# SCR_TC3xx register map
Vendor: Infineon; File version: 1.0
Registers are 8-bit, read-write, reset 0x0 unless marked. A register's access mark holds for its fields unless they carry their own. Offsets are from the block's base; [hi:lo] are bit positions; {n}, {i} and the like mark numbered series.

## SCR_SSC — SCR Synchronous serial channel
Base 0x00040000
0x09 SSC_CONOL ro — Control Register Low [Operation Mode] (SFR 0x89, RMAP 0)
  [3:0] BC — Bit Count Field. This field is loaded with the programmed data width value (BM) when the SSC is enabled. It then counts down with every shift bit. Note:This bit field is not to be written to. [rh]
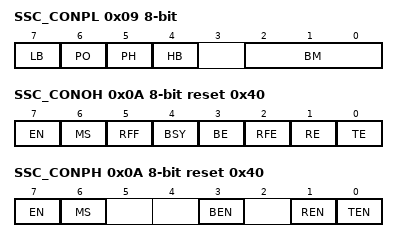
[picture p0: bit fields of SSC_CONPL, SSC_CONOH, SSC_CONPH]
0x09 SSC_CONPL (alternate view of SSC_CONOL) — Control Register Low [Programming Mode] (SFR 0x89, RMAP 0)
  [7] LB — Loop Back Control. This bit shall be set by software only in Master mode. [rw]
    0=NORMAL_OUTPUT; 1=RECEIVE_INPUT_IS_CONNECTED_WITH (Receive input is connected with transmit output (half-duplex mode))
  [6] PO — Clock Polarity Control. [rw]
    0=IDLE_LOW (Idle clock line is low, leading clock edge is low-to-high transition.); 1=IDLE_HIGH (Idle clock line is high, leading clock edge is high-to-low transition.)
  [5] PH — Clock Phase Control. [rw]
    0=LATCH_ON_TRAILING_EDGE (Shift transmit data on the leading clock edge, latch on trailing edge.); 1=LATCH_ON_LEADING_EDGE (Latch receive data on leading clock edge, shift on trailing edge.)
  [4] HB — Heading Control. [rw]
    0=LSB_FIRST (Transmit/Receive LSB First); 1=MSB_FIRST (Transmit/Receive MSB First)
  [2:0] BM — Data Width Selection. Note:The transfer and receive data width is maximum 8 bits. Transfer Data Width is 4...8 bits (<BM>+1). … [rw]
    0=RESERVED_DO_NOT_USE_THIS (Reserved. Do not use this combination.); 2=RESERVED_DO_NOT_USE_THIS_2 (Reserved. Do not use this combination.); {v}=TRANSFER_DATA_WIDTH_IS_{v+1}_BITS (v=3..7)
0x0A SSC_CONOH reset 0x40 — Control Register High [Operation Mode] (SFR 0x8A, RMAP 0)
  [7] EN — Enable Bit = 1 (needed for operating mode). Transmission and reception enabled. Access to status flags and M/S control. [rw]
  [6] MS — Master Select. This bit shall not be modified during operation mode. [rw]
    0=SLAVE_MODE_OPERATE_ON_SHIFT_CLOCK (Slave Mode. Operate on shift clock received via SCLK.); 1=MASTER_MODE_GENERATE_SHIFT_CLOCK (Master Mode. Generate shift clock and output it via SCLK.)
  [5] RFF ro — Receive FIFO Buffer Full Flag. Note:FIFO full will be deleted as soon as the receive buffer is read by software. [rh]
    0=RECEIVE_FIFO_IS_NOT_FULL; 1=RECEIVE_FIFO_IS_FULL
  [4] BSY ro — Busy Flag. Set while a transfer is in progress. Note: This bit is not to be written to. [rh]
    0=NO_TRANSFER_IN_PROGRESS; 1=TRANSFER_IN_PROGRESS
  [3] BE — Baudrate Error Flag. [rwh]
    0=NO_ERROR; 1=MORE_THAN_FACTOR_2_OR_0_5_BETWEEN (More than factor 2 or 0.5 between slave's actual and expected baudrate)
  [2] RFE ro — Receive FIFO Buffer Empty Flag. [rh]
    0=RECEIVE_FIFO_CONTAINS_DATA; 1=RECEIVE_FIFO_IS_EMPTY
  [1] RE — Receive Error Flag. [rwh]
    0=NO_ERROR; 1=RECEPTION_IN_FIFO_IS_BLOCKED
  [0] TE — Transmit Error Flag. [rwh]
    0=NO_ERROR; 1=TRANSFER_STARTS_WITH_THE_SLAVE_S (Transfer starts with the slave's transmit buffer not being updated)
0x0A SSC_CONPH reset 0x40 (alternate view of SSC_CONOH) — Control Register High [Programming Mode] (SFR 0x8A, RMAP 0)
  [7] EN — Enable Bit = 0 (needed for programming mode). Transmission and reception disabled. Access to control bits. [rw]
  [6] MS — Master Select. This bit shall not be changed during operation mode. [rw]
    0=SLAVE (Slave Mode. Operate on shift clock received via SCLK.); 1=MASTER (Master Mode. Generate shift clock and output it via SCLK.)
  [3] BEN — Baudrate Error Enable. [rw]
    0=IGNORE_BAUDRATE_ERRORS; 1=CHECK_BAUDRATE_ERRORS
  [1] REN — Receive Error Enable. [rw]
    0=IGNORE_RECEIVE_ERRORS; 1=CHECK_RECEIVE_ERRORS
  [0] TEN — Transmit Error Enable. [rw]
    0=IGNORE_TRANSMIT_ERRORS; 1=CHECK_TRANSMIT_ERRORS
0x0B SSC_TBL — Transmitter Buffer Register (SFR 0x8B, RMAP 0)
  [7:0] TB_VALUE — Transmit Data Register Value. TB_VALUE is the data value to be transmitted. Unselected bits of TB_VALUE are ignored during transmission. [rw]
0x0C SSC_RBL ro — Receiver Buffer Register (SFR 0x8C, RMAP 0)
  [7:0] RB_VALUE — Receive Data Register Value. SSC_RBL contains the received data value RB_VALUE. Unselected bits of RB_VALUE will be not valid and should be ignored. Access point to FIFO. In case of FIFO overflow, the receive FIFO is blocked. [rh]
0x0D SSC_BRL — Baud Rate Timer Reload Register Low (SFR 0x8D, RMAP 0)
  [7:0] BR_VALUE — Baud Rate Timer Reload Register Value, low byte. Represents the lower 8 bits of the 16-bit baudrate reload value. [rw]
0x0E SSC_BRH — Baud Rate Timer Reload Register High (SFR 0x8E, RMAP 0)
  [7:0] BR_VALUE — Baud Rate Timer Reload Register Value, high byte. Represents the upper 8 bits of the 16-bit baudrate reload value. [rw]
